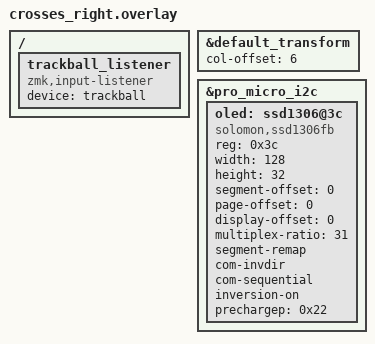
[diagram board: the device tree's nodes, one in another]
#include "crosses.dtsi"

&default_transform {
    col-offset = <6>;
}; 

/ {
    trackball_listener {
        compatible = "zmk,input-listener";
        device = <&trackball>;
    };
};

&pro_micro_i2c {
    status = "okay";
    oled: ssd1306@3c {
        compatible = "solomon,ssd1306fb";
        reg = <0x3c>;
        width = <128>;
        height = <32>;
        segment-offset = <0>;
        page-offset = <0>;
        display-offset = <0>;
        multiplex-ratio = <31>;
        segment-remap;
        com-invdir;
        com-sequential;
        inversion-on;
        prechargep = <0x22>;
    };
};
